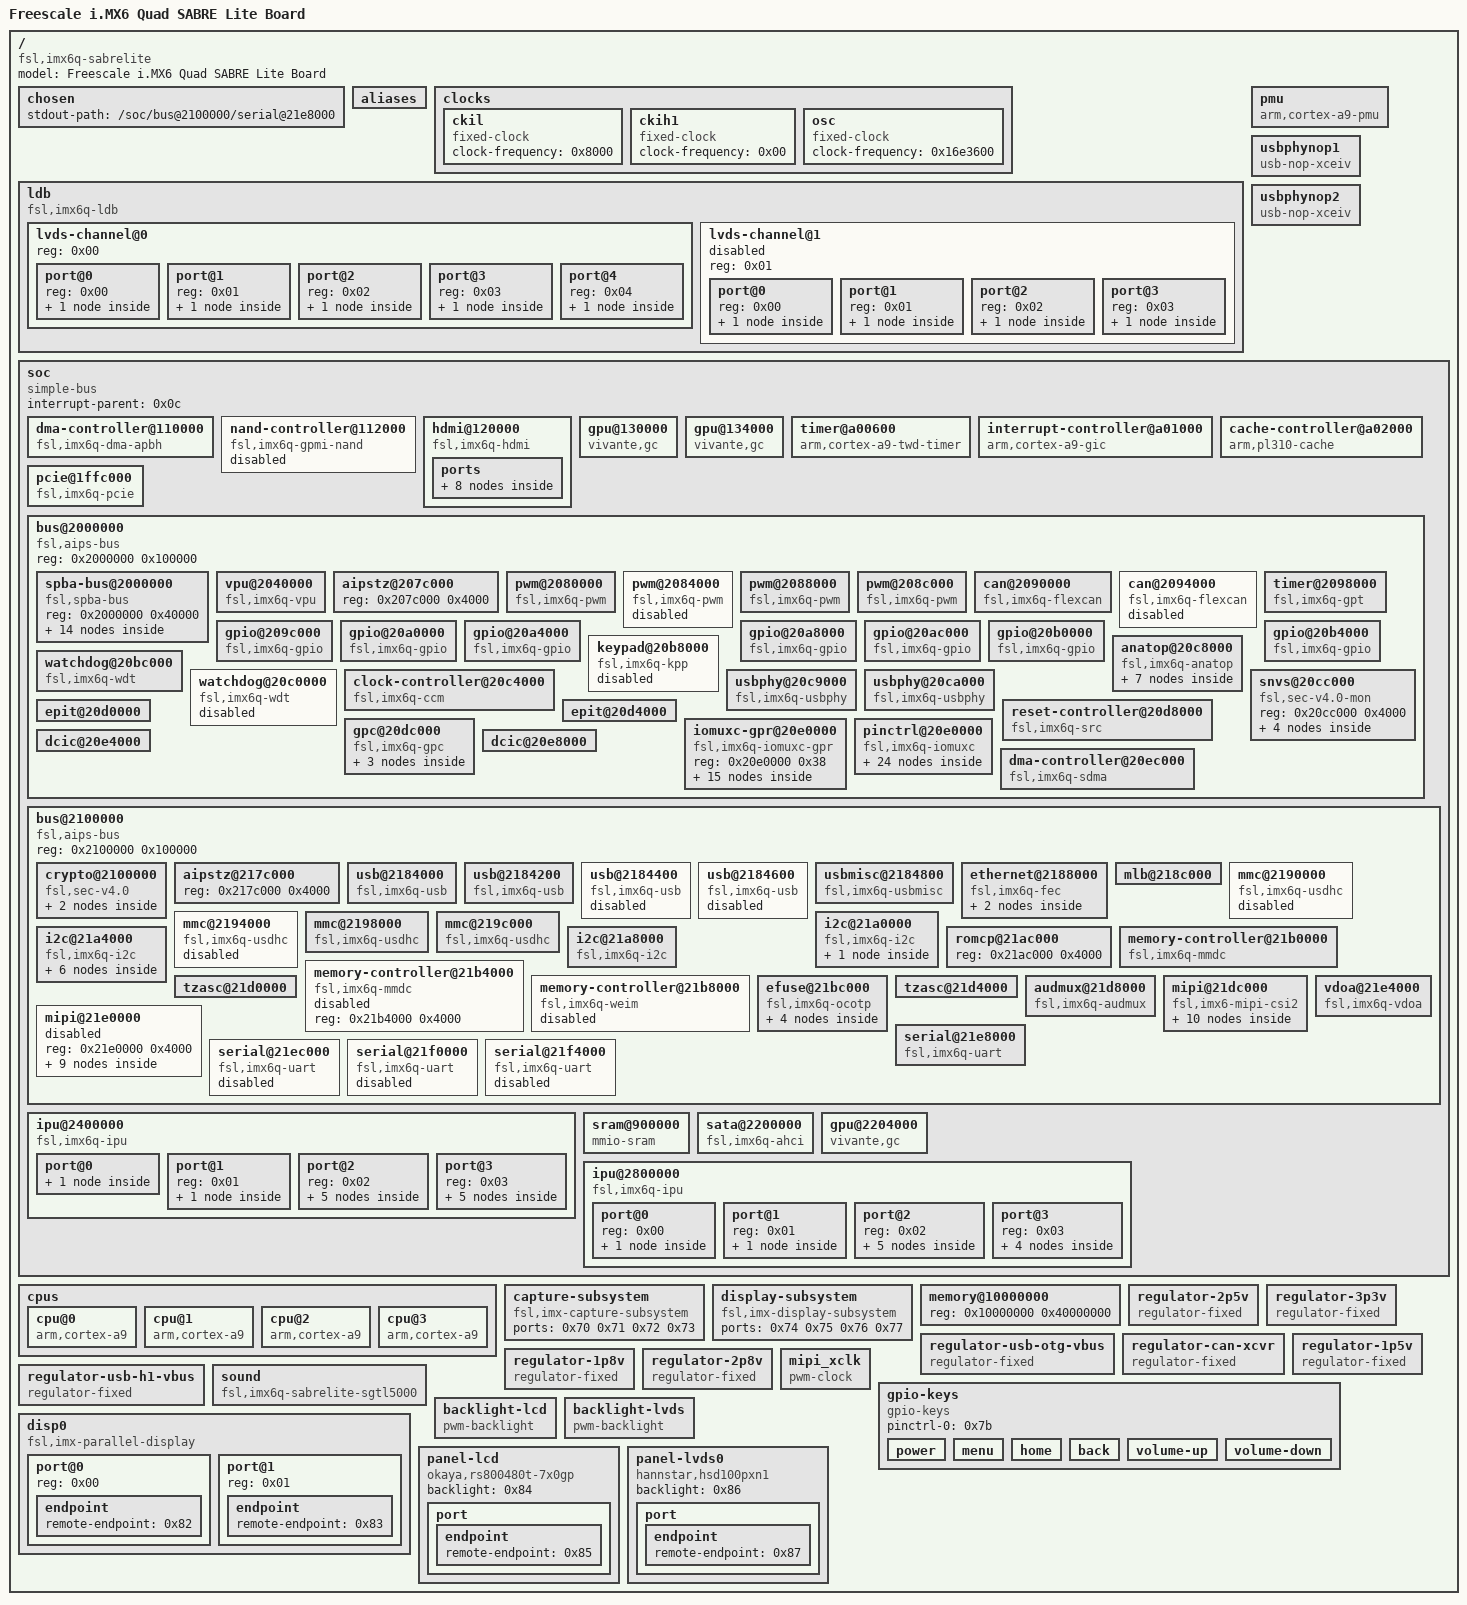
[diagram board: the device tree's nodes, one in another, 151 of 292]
/*
 * Copyright Linux Kernel Team
 *
 * SPDX-License-Identifier: GPL-2.0-only
 *
 * This file is derived from an intermediate build stage of the
 * Linux kernel. The licenses of all input files to this process
 * are compatible with GPL-2.0-only.
 */

/dts-v1/;

/ {
	#address-cells = <0x01>;
	#size-cells = <0x01>;
	model = "Freescale i.MX6 Quad SABRE Lite Board";
	compatible = "fsl,imx6q-sabrelite", "fsl,imx6q";

	chosen {
		stdout-path = "/soc/bus@2100000/serial@21e8000";
	};

	aliases {
		ethernet0 = "/soc/bus@2100000/ethernet@2188000";
		can0 = "/soc/bus@2000000/can@2090000";
		can1 = "/soc/bus@2000000/can@2094000";
		gpio0 = "/soc/bus@2000000/gpio@209c000";
		gpio1 = "/soc/bus@2000000/gpio@20a0000";
		gpio2 = "/soc/bus@2000000/gpio@20a4000";
		gpio3 = "/soc/bus@2000000/gpio@20a8000";
		gpio4 = "/soc/bus@2000000/gpio@20ac000";
		gpio5 = "/soc/bus@2000000/gpio@20b0000";
		gpio6 = "/soc/bus@2000000/gpio@20b4000";
		i2c0 = "/soc/bus@2100000/i2c@21a0000";
		i2c1 = "/soc/bus@2100000/i2c@21a4000";
		i2c2 = "/soc/bus@2100000/i2c@21a8000";
		ipu0 = "/soc/ipu@2400000";
		mmc0 = "/soc/bus@2100000/mmc@2198000";
		mmc1 = "/soc/bus@2100000/mmc@219c000";
		mmc2 = "/soc/bus@2100000/mmc@2198000";
		mmc3 = "/soc/bus@2100000/mmc@219c000";
		serial0 = "/soc/bus@2000000/spba-bus@2000000/serial@2020000";
		serial1 = "/soc/bus@2100000/serial@21e8000";
		serial2 = "/soc/bus@2100000/serial@21ec000";
		serial3 = "/soc/bus@2100000/serial@21f0000";
		serial4 = "/soc/bus@2100000/serial@21f4000";
		spi0 = "/soc/bus@2000000/spba-bus@2000000/spi@2008000";
		spi1 = "/soc/bus@2000000/spba-bus@2000000/spi@200c000";
		spi2 = "/soc/bus@2000000/spba-bus@2000000/spi@2010000";
		spi3 = "/soc/bus@2000000/spba-bus@2000000/spi@2014000";
		usb0 = "/soc/bus@2100000/usb@2184000";
		usb1 = "/soc/bus@2100000/usb@2184200";
		usb2 = "/soc/bus@2100000/usb@2184400";
		usb3 = "/soc/bus@2100000/usb@2184600";
		usbphy0 = "/soc/bus@2000000/usbphy@20c9000";
		usbphy1 = "/soc/bus@2000000/usbphy@20ca000";
		ipu1 = "/soc/ipu@2800000";
		spi4 = "/soc/bus@2000000/spba-bus@2000000/spi@2018000";
	};

	clocks {

		ckil {
			compatible = "fixed-clock";
			#clock-cells = <0x00>;
			clock-frequency = <0x8000>;
		};

		ckih1 {
			compatible = "fixed-clock";
			#clock-cells = <0x00>;
			clock-frequency = <0x00>;
		};

		osc {
			compatible = "fixed-clock";
			#clock-cells = <0x00>;
			clock-frequency = <0x16e3600>;
		};
	};

	ldb {
		#address-cells = <0x01>;
		#size-cells = <0x00>;
		compatible = "fsl,imx6q-ldb", "fsl,imx53-ldb";
		gpr = <0x01>;
		status = "okay";
		clocks = <0x02 0x21 0x02 0x22 0x02 0x27 0x02 0x28 0x02 0x29 0x02 0x2a 0x02 0x87 0x02 0x88>;
		clock-names = "di0_pll", "di1_pll", "di0_sel", "di1_sel", "di2_sel", "di3_sel", "di0", "di1";

		lvds-channel@0 {
			#address-cells = <0x01>;
			#size-cells = <0x00>;
			reg = <0x00>;
			status = "okay";

			port@0 {
				reg = <0x00>;

				endpoint {
					remote-endpoint = <0x03>;
					phandle = <0x5c>;
				};
			};

			port@1 {
				reg = <0x01>;

				endpoint {
					remote-endpoint = <0x04>;
					phandle = <0x60>;
				};
			};

			port@2 {
				reg = <0x02>;

				endpoint {
					remote-endpoint = <0x05>;
					phandle = <0x66>;
				};
			};

			port@3 {
				reg = <0x03>;

				endpoint {
					remote-endpoint = <0x06>;
					phandle = <0x6a>;
				};
			};

			port@4 {
				reg = <0x04>;

				endpoint {
					remote-endpoint = <0x07>;
					phandle = <0x87>;
				};
			};
		};

		lvds-channel@1 {
			#address-cells = <0x01>;
			#size-cells = <0x00>;
			reg = <0x01>;
			status = "disabled";

			port@0 {
				reg = <0x00>;

				endpoint {
					remote-endpoint = <0x08>;
					phandle = <0x5d>;
				};
			};

			port@1 {
				reg = <0x01>;

				endpoint {
					remote-endpoint = <0x09>;
					phandle = <0x61>;
				};
			};

			port@2 {
				reg = <0x02>;

				endpoint {
					remote-endpoint = <0x0a>;
					phandle = <0x67>;
				};
			};

			port@3 {
				reg = <0x03>;

				endpoint {
					remote-endpoint = <0x0b>;
					phandle = <0x6b>;
				};
			};
		};
	};

	pmu {
		compatible = "arm,cortex-a9-pmu";
		interrupt-parent = <0x0c>;
		interrupts = <0x00 0x5e 0x04>;
	};

	usbphynop1 {
		compatible = "usb-nop-xceiv";
		#phy-cells = <0x00>;
		phandle = <0x33>;
	};

	usbphynop2 {
		compatible = "usb-nop-xceiv";
		#phy-cells = <0x00>;
		phandle = <0x34>;
	};

	soc {
		#address-cells = <0x01>;
		#size-cells = <0x01>;
		compatible = "simple-bus";
		interrupt-parent = <0x0c>;
		ranges;

		dma-controller@110000 {
			compatible = "fsl,imx6q-dma-apbh", "fsl,imx28-dma-apbh";
			reg = <0x110000 0x2000>;
			interrupts = <0x00 0x0d 0x04 0x00 0x0d 0x04 0x00 0x0d 0x04 0x00 0x0d 0x04>;
			#dma-cells = <0x01>;
			dma-channels = <0x04>;
			clocks = <0x02 0x6a>;
			phandle = <0x0d>;
		};

		nand-controller@112000 {
			compatible = "fsl,imx6q-gpmi-nand";
			reg = <0x112000 0x2000 0x114000 0x2000>;
			reg-names = "gpmi-nand", "bch";
			interrupts = <0x00 0x0f 0x04>;
			interrupt-names = "bch";
			clocks = <0x02 0x98 0x02 0x99 0x02 0x97 0x02 0x96 0x02 0x95>;
			clock-names = "gpmi_io", "gpmi_apb", "gpmi_bch", "gpmi_bch_apb", "per1_bch";
			dmas = <0x0d 0x00>;
			dma-names = "rx-tx";
			status = "disabled";
		};

		hdmi@120000 {
			reg = <0x120000 0x9000>;
			interrupts = <0x00 0x73 0x04>;
			gpr = <0x01>;
			clocks = <0x02 0x7b 0x02 0x7c>;
			clock-names = "iahb", "isfr";
			status = "okay";
			compatible = "fsl,imx6q-hdmi";
			ddc-i2c-bus = <0x0e>;

			ports {
				#address-cells = <0x01>;
				#size-cells = <0x00>;

				port@0 {
					reg = <0x00>;

					endpoint {
						remote-endpoint = <0x0f>;
						phandle = <0x5a>;
					};
				};

				port@1 {
					reg = <0x01>;

					endpoint {
						remote-endpoint = <0x10>;
						phandle = <0x5e>;
					};
				};

				port@2 {
					reg = <0x02>;

					endpoint {
						remote-endpoint = <0x11>;
						phandle = <0x64>;
					};
				};

				port@3 {
					reg = <0x03>;

					endpoint {
						remote-endpoint = <0x12>;
						phandle = <0x68>;
					};
				};
			};
		};

		gpu@130000 {
			compatible = "vivante,gc";
			reg = <0x130000 0x4000>;
			interrupts = <0x00 0x09 0x04>;
			clocks = <0x02 0x1b 0x02 0x7a 0x02 0x4a>;
			clock-names = "bus", "core", "shader";
			power-domains = <0x13>;
			#cooling-cells = <0x02>;
		};

		gpu@134000 {
			compatible = "vivante,gc";
			reg = <0x134000 0x4000>;
			interrupts = <0x00 0x0a 0x04>;
			clocks = <0x02 0x1a 0x02 0x79>;
			clock-names = "bus", "core";
			power-domains = <0x13>;
			#cooling-cells = <0x02>;
		};

		timer@a00600 {
			compatible = "arm,cortex-a9-twd-timer";
			reg = <0xa00600 0x20>;
			interrupts = <0x01 0x0d 0xf01>;
			interrupt-parent = <0x14>;
			clocks = <0x02 0x0f>;
		};

		interrupt-controller@a01000 {
			compatible = "arm,cortex-a9-gic";
			#interrupt-cells = <0x03>;
			interrupt-controller;
			reg = <0xa01000 0x1000 0xa00100 0x100>;
			interrupt-parent = <0x14>;
			phandle = <0x14>;
		};

		cache-controller@a02000 {
			compatible = "arm,pl310-cache";
			reg = <0xa02000 0x1000>;
			interrupts = <0x00 0x5c 0x04>;
			cache-unified;
			cache-level = <0x02>;
			arm,tag-latency = <0x04 0x02 0x03>;
			arm,data-latency = <0x04 0x02 0x03>;
			arm,shared-override;
			phandle = <0x6c>;
		};

		pcie@1ffc000 {
			compatible = "fsl,imx6q-pcie";
			reg = <0x1ffc000 0x4000 0x1f00000 0x80000>;
			reg-names = "dbi", "config";
			#address-cells = <0x03>;
			#size-cells = <0x02>;
			device_type = "pci";
			bus-range = <0x00 0xff>;
			ranges = <0x81000000 0x00 0x00 0x1f80000 0x00 0x10000 0x82000000 0x00 0x1000000 0x1000000 0x00 0xf00000>;
			num-lanes = <0x01>;
			interrupts = <0x00 0x78 0x04>;
			interrupt-names = "msi";
			#interrupt-cells = <0x01>;
			interrupt-map-mask = <0x00 0x00 0x00 0x07>;
			interrupt-map = <0x00 0x00 0x00 0x01 0x0c 0x00 0x7b 0x04 0x00 0x00 0x00 0x02 0x0c 0x00 0x7a 0x04 0x00 0x00 0x00 0x03 0x0c 0x00 0x79 0x04 0x00 0x00 0x00 0x04 0x0c 0x00 0x78 0x04>;
			clocks = <0x02 0x90 0x02 0xce 0x02 0xbd>;
			clock-names = "pcie", "pcie_bus", "pcie_phy";
			status = "okay";
		};

		bus@2000000 {
			compatible = "fsl,aips-bus", "simple-bus";
			#address-cells = <0x01>;
			#size-cells = <0x01>;
			reg = <0x2000000 0x100000>;
			ranges;

			spba-bus@2000000 {
				compatible = "fsl,spba-bus", "simple-bus";
				#address-cells = <0x01>;
				#size-cells = <0x01>;
				reg = <0x2000000 0x40000>;
				ranges;

				spdif@2004000 {
					compatible = "fsl,imx35-spdif";
					reg = <0x2004000 0x4000>;
					interrupts = <0x00 0x34 0x04>;
					dmas = <0x15 0x0e 0x12 0x00 0x15 0x0f 0x12 0x00>;
					dma-names = "rx", "tx";
					clocks = <0x02 0xf4 0x02 0x03 0x02 0xc5 0x02 0x6b 0x02 0x00 0x02 0x76 0x02 0x3e 0x02 0x00 0x02 0x00 0x02 0x9c>;
					clock-names = "core", "rxtx0", "rxtx1", "rxtx2", "rxtx3", "rxtx4", "rxtx5", "rxtx6", "rxtx7", "spba";
					status = "disabled";
				};

				spi@2008000 {
					#address-cells = <0x01>;
					#size-cells = <0x00>;
					compatible = "fsl,imx6q-ecspi", "fsl,imx51-ecspi";
					reg = <0x2008000 0x4000>;
					interrupts = <0x00 0x1f 0x04>;
					clocks = <0x02 0x70 0x02 0x70>;
					clock-names = "ipg", "per";
					dmas = <0x15 0x03 0x07 0x01 0x15 0x04 0x07 0x02>;
					dma-names = "rx", "tx";
					status = "okay";
					cs-gpios = <0x16 0x13 0x01>;
					pinctrl-names = "default";
					pinctrl-0 = <0x17>;

					flash@0 {
						compatible = "sst,sst25vf016b", "jedec,spi-nor";
						spi-max-frequency = <0x1312d00>;
						reg = <0x00>;
					};
				};

				spi@200c000 {
					#address-cells = <0x01>;
					#size-cells = <0x00>;
					compatible = "fsl,imx6q-ecspi", "fsl,imx51-ecspi";
					reg = <0x200c000 0x4000>;
					interrupts = <0x00 0x20 0x04>;
					clocks = <0x02 0x71 0x02 0x71>;
					clock-names = "ipg", "per";
					dmas = <0x15 0x05 0x07 0x01 0x15 0x06 0x07 0x02>;
					dma-names = "rx", "tx";
					status = "disabled";
				};

				spi@2010000 {
					#address-cells = <0x01>;
					#size-cells = <0x00>;
					compatible = "fsl,imx6q-ecspi", "fsl,imx51-ecspi";
					reg = <0x2010000 0x4000>;
					interrupts = <0x00 0x21 0x04>;
					clocks = <0x02 0x72 0x02 0x72>;
					clock-names = "ipg", "per";
					dmas = <0x15 0x07 0x07 0x01 0x15 0x08 0x07 0x02>;
					dma-names = "rx", "tx";
					status = "disabled";
				};

				spi@2014000 {
					#address-cells = <0x01>;
					#size-cells = <0x00>;
					compatible = "fsl,imx6q-ecspi", "fsl,imx51-ecspi";
					reg = <0x2014000 0x4000>;
					interrupts = <0x00 0x22 0x04>;
					clocks = <0x02 0x73 0x02 0x73>;
					clock-names = "ipg", "per";
					dmas = <0x15 0x09 0x07 0x01 0x15 0x0a 0x07 0x02>;
					dma-names = "rx", "tx";
					status = "disabled";
				};

				serial@2020000 {
					compatible = "fsl,imx6q-uart", "fsl,imx21-uart";
					reg = <0x2020000 0x4000>;
					interrupts = <0x00 0x1a 0x04>;
					clocks = <0x02 0xa0 0x02 0xa1>;
					clock-names = "ipg", "per";
					dmas = <0x15 0x19 0x04 0x00 0x15 0x1a 0x04 0x00>;
					dma-names = "rx", "tx";
					status = "okay";
					pinctrl-names = "default";
					pinctrl-0 = <0x18>;
				};

				esai@2024000 {
					#sound-dai-cells = <0x00>;
					compatible = "fsl,imx35-esai";
					reg = <0x2024000 0x4000>;
					interrupts = <0x00 0x33 0x04>;
					clocks = <0x02 0xd0 0x02 0x76 0x02 0xd0 0x02 0x9c>;
					clock-names = "core", "extal", "fsys", "spba";
					dmas = <0x15 0x17 0x15 0x00 0x15 0x18 0x15 0x00>;
					dma-names = "rx", "tx";
					status = "disabled";
				};

				ssi@2028000 {
					#sound-dai-cells = <0x00>;
					compatible = "fsl,imx6q-ssi", "fsl,imx51-ssi";
					reg = <0x2028000 0x4000>;
					interrupts = <0x00 0x2e 0x04>;
					clocks = <0x02 0xb2 0x02 0x9d>;
					clock-names = "ipg", "baud";
					dmas = <0x15 0x25 0x01 0x00 0x15 0x26 0x01 0x00>;
					dma-names = "rx", "tx";
					fsl,fifo-depth = <0x0f>;
					status = "okay";
					phandle = <0x7d>;
				};

				ssi@202c000 {
					#sound-dai-cells = <0x00>;
					compatible = "fsl,imx6q-ssi", "fsl,imx51-ssi";
					reg = <0x202c000 0x4000>;
					interrupts = <0x00 0x2f 0x04>;
					clocks = <0x02 0xb3 0x02 0x9e>;
					clock-names = "ipg", "baud";
					dmas = <0x15 0x29 0x01 0x00 0x15 0x2a 0x01 0x00>;
					dma-names = "rx", "tx";
					fsl,fifo-depth = <0x0f>;
					status = "disabled";
				};

				ssi@2030000 {
					#sound-dai-cells = <0x00>;
					compatible = "fsl,imx6q-ssi", "fsl,imx51-ssi";
					reg = <0x2030000 0x4000>;
					interrupts = <0x00 0x30 0x04>;
					clocks = <0x02 0xb4 0x02 0x9f>;
					clock-names = "ipg", "baud";
					dmas = <0x15 0x2d 0x01 0x00 0x15 0x2e 0x01 0x00>;
					dma-names = "rx", "tx";
					fsl,fifo-depth = <0x0f>;
					status = "disabled";
				};

				asrc@2034000 {
					compatible = "fsl,imx53-asrc";
					reg = <0x2034000 0x4000>;
					interrupts = <0x00 0x32 0x04>;
					clocks = <0x02 0xd2 0x02 0xd3 0x02 0x00 0x02 0x00 0x02 0x00 0x02 0x00 0x02 0x00 0x02 0x00 0x02 0x00 0x02 0x00 0x02 0x00 0x02 0x00 0x02 0x00 0x02 0x00 0x02 0x00 0x02 0x6b 0x02 0x00 0x02 0x00 0x02 0x9c>;
					clock-names = "mem", "ipg", "asrck_0", "asrck_1", "asrck_2", "asrck_3", "asrck_4", "asrck_5", "asrck_6", "asrck_7", "asrck_8", "asrck_9", "asrck_a", "asrck_b", "asrck_c", "asrck_d", "asrck_e", "asrck_f", "spba";
					dmas = <0x15 0x11 0x17 0x01 0x15 0x12 0x17 0x01 0x15 0x13 0x17 0x01 0x15 0x14 0x17 0x01 0x15 0x15 0x17 0x01 0x15 0x16 0x17 0x01>;
					dma-names = "rxa", "rxb", "rxc", "txa", "txb", "txc";
					fsl,asrc-rate = <0xbb80>;
					fsl,asrc-width = <0x10>;
					status = "okay";
				};

				spba-bus@203c000 {
					reg = <0x203c000 0x4000>;
				};

				spi@2018000 {
					#address-cells = <0x01>;
					#size-cells = <0x00>;
					compatible = "fsl,imx6q-ecspi", "fsl,imx51-ecspi";
					reg = <0x2018000 0x4000>;
					interrupts = <0x00 0x23 0x04>;
					clocks = <0x02 0x74 0x02 0x74>;
					clock-names = "ipg", "per";
					dmas = <0x15 0x0b 0x07 0x01 0x15 0x0c 0x07 0x02>;
					dma-names = "rx", "tx";
					status = "disabled";
				};
			};

			vpu@2040000 {
				compatible = "fsl,imx6q-vpu", "cnm,coda960";
				reg = <0x2040000 0x3c000>;
				interrupts = <0x00 0x0c 0x04 0x00 0x03 0x04>;
				interrupt-names = "bit", "jpeg";
				clocks = <0x02 0xa8 0x02 0x8c>;
				clock-names = "per", "ahb";
				power-domains = <0x13>;
				resets = <0x19 0x01>;
				iram = <0x1a>;
			};

			aipstz@207c000 {
				reg = <0x207c000 0x4000>;
			};

			pwm@2080000 {
				#pwm-cells = <0x03>;
				compatible = "fsl,imx6q-pwm", "fsl,imx27-pwm";
				reg = <0x2080000 0x4000>;
				interrupts = <0x00 0x53 0x04>;
				clocks = <0x02 0x3e 0x02 0x91>;
				clock-names = "ipg", "per";
				status = "okay";
				pinctrl-names = "default";
				pinctrl-0 = <0x1b>;
				phandle = <0x7f>;
			};

			pwm@2084000 {
				#pwm-cells = <0x03>;
				compatible = "fsl,imx6q-pwm", "fsl,imx27-pwm";
				reg = <0x2084000 0x4000>;
				interrupts = <0x00 0x54 0x04>;
				clocks = <0x02 0x3e 0x02 0x92>;
				clock-names = "ipg", "per";
				status = "disabled";
			};

			pwm@2088000 {
				#pwm-cells = <0x03>;
				compatible = "fsl,imx6q-pwm", "fsl,imx27-pwm";
				reg = <0x2088000 0x4000>;
				interrupts = <0x00 0x55 0x04>;
				clocks = <0x02 0x3e 0x02 0x93>;
				clock-names = "ipg", "per";
				status = "okay";
				pinctrl-names = "default";
				pinctrl-0 = <0x1c>;
				phandle = <0x7a>;
			};

			pwm@208c000 {
				#pwm-cells = <0x03>;
				compatible = "fsl,imx6q-pwm", "fsl,imx27-pwm";
				reg = <0x208c000 0x4000>;
				interrupts = <0x00 0x56 0x04>;
				clocks = <0x02 0x3e 0x02 0x94>;
				clock-names = "ipg", "per";
				status = "okay";
				pinctrl-names = "default";
				pinctrl-0 = <0x1d>;
				phandle = <0x80>;
			};

			can@2090000 {
				compatible = "fsl,imx6q-flexcan";
				reg = <0x2090000 0x4000>;
				interrupts = <0x00 0x6e 0x04>;
				clocks = <0x02 0x6c 0x02 0x6d>;
				clock-names = "ipg", "per";
				fsl,stop-mode = <0x01 0x34 0x1c>;
				status = "okay";
				pinctrl-names = "default";
				pinctrl-0 = <0x1e>;
				xceiver-supply = <0x1f>;
			};

			can@2094000 {
				compatible = "fsl,imx6q-flexcan";
				reg = <0x2094000 0x4000>;
				interrupts = <0x00 0x6f 0x04>;
				clocks = <0x02 0x6e 0x02 0x6f>;
				clock-names = "ipg", "per";
				fsl,stop-mode = <0x01 0x34 0x1d>;
				status = "disabled";
			};

			timer@2098000 {
				compatible = "fsl,imx6q-gpt", "fsl,imx31-gpt";
				reg = <0x2098000 0x4000>;
				interrupts = <0x00 0x37 0x04>;
				clocks = <0x02 0x77 0x02 0x78 0x02 0xed>;
				clock-names = "ipg", "per", "osc_per";
			};

			gpio@209c000 {
				compatible = "fsl,imx6q-gpio", "fsl,imx35-gpio";
				reg = <0x209c000 0x4000>;
				interrupts = <0x00 0x42 0x04 0x00 0x43 0x04>;
				gpio-controller;
				#gpio-cells = <0x02>;
				interrupt-controller;
				#interrupt-cells = <0x02>;
				gpio-ranges = <0x20 0x00 0x88 0x02 0x20 0x02 0x8d 0x01 0x20 0x03 0x8b 0x01 0x20 0x04 0x8e 0x02 0x20 0x06 0x8c 0x01 0x20 0x07 0x90 0x02 0x20 0x09 0x8a 0x01 0x20 0x0a 0xd5 0x03 0x20 0x0d 0x14 0x01 0x20 0x0e 0x13 0x01 0x20 0x0f 0x15 0x01 0x20 0x10 0xd0 0x01 0x20 0x11 0xcf 0x01 0x20 0x12 0xd2 0x03 0x20 0x15 0xd1 0x01 0x20 0x16 0x74 0x0a>;
				phandle = <0x48>;
			};

			gpio@20a0000 {
				compatible = "fsl,imx6q-gpio", "fsl,imx35-gpio";
				reg = <0x20a0000 0x4000>;
				interrupts = <0x00 0x44 0x04 0x00 0x45 0x04>;
				gpio-controller;
				#gpio-cells = <0x02>;
				interrupt-controller;
				#interrupt-cells = <0x02>;
				gpio-ranges = <0x20 0x00 0xbf 0x10 0x20 0x10 0x37 0x0e 0x20 0x1e 0x23 0x01 0x20 0x1f 0x2c 0x01>;
				phandle = <0x3c>;
			};

			gpio@20a4000 {
				compatible = "fsl,imx6q-gpio", "fsl,imx35-gpio";
				reg = <0x20a4000 0x4000>;
				interrupts = <0x00 0x46 0x04 0x00 0x47 0x04>;
				gpio-controller;
				#gpio-cells = <0x02>;
				interrupt-controller;
				#interrupt-cells = <0x02>;
				gpio-ranges = <0x20 0x00 0x45 0x10 0x20 0x10 0x24 0x08 0x20 0x18 0x2d 0x08>;
				phandle = <0x16>;
			};

			gpio@20a8000 {
				compatible = "fsl,imx6q-gpio", "fsl,imx35-gpio";
				reg = <0x20a8000 0x4000>;
				interrupts = <0x00 0x48 0x04 0x00 0x49 0x04>;
				gpio-controller;
				#gpio-cells = <0x02>;
				interrupt-controller;
				#interrupt-cells = <0x02>;
				gpio-ranges = <0x20 0x05 0x95 0x01 0x20 0x06 0x7e 0x0a 0x20 0x10 0x57 0x10>;
				phandle = <0x7c>;
			};

			gpio@20ac000 {
				compatible = "fsl,imx6q-gpio", "fsl,imx35-gpio";
				reg = <0x20ac000 0x4000>;
				interrupts = <0x00 0x4a 0x04 0x00 0x4b 0x04>;
				gpio-controller;
				#gpio-cells = <0x02>;
				interrupt-controller;
				#interrupt-cells = <0x02>;
				gpio-ranges = <0x20 0x00 0x55 0x01 0x20 0x02 0x22 0x01 0x20 0x04 0x35 0x01 0x20 0x05 0x67 0x0d 0x20 0x12 0x96 0x0e>;
			};

			gpio@20b0000 {
				compatible = "fsl,imx6q-gpio", "fsl,imx35-gpio";
				reg = <0x20b0000 0x4000>;
				interrupts = <0x00 0x4c 0x04 0x00 0x4d 0x04>;
				gpio-controller;
				#gpio-cells = <0x02>;
				interrupt-controller;
				#interrupt-cells = <0x02>;
				gpio-ranges = <0x20 0x00 0xa4 0x06 0x20 0x06 0x36 0x01 0x20 0x07 0xb5 0x05 0x20 0x0e 0xba 0x03 0x20 0x11 0xaa 0x02 0x20 0x13 0x16 0x0c 0x20 0x1f 0x56 0x01>;
				phandle = <0x45>;
			};

			gpio@20b4000 {
				compatible = "fsl,imx6q-gpio", "fsl,imx35-gpio";
				reg = <0x20b4000 0x4000>;
				interrupts = <0x00 0x4e 0x04 0x00 0x4f 0x04>;
				gpio-controller;
				#gpio-cells = <0x02>;
				interrupt-controller;
				#interrupt-cells = <0x02>;
				gpio-ranges = <0x20 0x00 0xac 0x09 0x20 0x09 0xbd 0x02 0x20 0x0b 0x92 0x03>;
				phandle = <0x39>;
			};

			keypad@20b8000 {
				compatible = "fsl,imx6q-kpp", "fsl,imx21-kpp";
				reg = <0x20b8000 0x4000>;
				interrupts = <0x00 0x52 0x04>;
				clocks = <0x02 0x3e>;
				status = "disabled";
			};

			watchdog@20bc000 {
				compatible = "fsl,imx6q-wdt", "fsl,imx21-wdt";
				reg = <0x20bc000 0x4000>;
				interrupts = <0x00 0x50 0x04>;
				clocks = <0x02 0x3e>;
			};

			watchdog@20c0000 {
				compatible = "fsl,imx6q-wdt", "fsl,imx21-wdt";
				reg = <0x20c0000 0x4000>;
				interrupts = <0x00 0x51 0x04>;
				clocks = <0x02 0x3e>;
				status = "disabled";
			};

			clock-controller@20c4000 {
				compatible = "fsl,imx6q-ccm";
				reg = <0x20c4000 0x4000>;
				interrupts = <0x00 0x57 0x04 0x00 0x58 0x04>;
				#clock-cells = <0x01>;
				assigned-clocks = <0x02 0x21 0x02 0x22>;
				assigned-clock-parents = <0x02 0xac 0x02 0xac>;
				phandle = <0x02>;
			};

			anatop@20c8000 {
				compatible = "fsl,imx6q-anatop", "syscon", "simple-mfd";
				reg = <0x20c8000 0x1000>;
				interrupts = <0x00 0x31 0x04 0x00 0x36 0x04 0x00 0x7f 0x04>;
				phandle = <0x21>;

				regulator-1p1 {
					compatible = "fsl,anatop-regulator";
					regulator-name = "vdd1p1";
					regulator-min-microvolt = <0xf4240>;
					regulator-max-microvolt = <0x124f80>;
					regulator-always-on;
					anatop-reg-offset = <0x110>;
					anatop-vol-bit-shift = <0x08>;
					anatop-vol-bit-width = <0x05>;
					anatop-min-bit-val = <0x04>;
					anatop-min-voltage = "", "\f5";
					anatop-max-voltage = <0x14fb18>;
					anatop-enable-bit = <0x00>;
				};

				regulator-3p0 {
					compatible = "fsl,anatop-regulator";
					regulator-name = "vdd3p0";
					regulator-min-microvolt = <0x2ab980>;
					regulator-max-microvolt = <0x3010b0>;
					regulator-always-on;
					anatop-reg-offset = <0x120>;
					anatop-vol-bit-shift = <0x08>;
					anatop-vol-bit-width = <0x05>;
					anatop-min-bit-val = <0x00>;
					anatop-min-voltage = <0x280de8>;
					anatop-max-voltage = <0x33e140>;
					anatop-enable-bit = <0x00>;
				};

				regulator-2p5 {
					compatible = "fsl,anatop-regulator";
					regulator-name = "vdd2p5";
					regulator-min-microvolt = <0x225510>;
					regulator-max-microvolt = <0x29f630>;
					regulator-always-on;
					anatop-reg-offset = <0x130>;
					anatop-vol-bit-shift = <0x08>;
					anatop-vol-bit-width = <0x05>;
					anatop-min-bit-val = <0x00>;
					anatop-min-voltage = <0x200b20>;
					anatop-max-voltage = <0x2bde78>;
					anatop-enable-bit = <0x00>;
				};

				regulator-vddcore {
					compatible = "fsl,anatop-regulator";
					regulator-name = "vddarm";
					regulator-min-microvolt = <0xb1008>;
					regulator-max-microvolt = <0x162010>;
					regulator-always-on;
					anatop-reg-offset = <0x140>;
					anatop-vol-bit-shift = <0x00>;
					anatop-vol-bit-width = <0x05>;
					anatop-delay-reg-offset = <0x170>;
					anatop-delay-bit-shift = <0x18>;
					anatop-delay-bit-width = <0x02>;
					anatop-min-bit-val = <0x01>;
					anatop-min-voltage = <0xb1008>;
					anatop-max-voltage = <0x162010>;
					phandle = <0x6d>;
				};

				regulator-vddpu {
					compatible = "fsl,anatop-regulator";
					regulator-name = "vddpu";
					regulator-min-microvolt = <0xb1008>;
					regulator-max-microvolt = <0x162010>;
					regulator-enable-ramp-delay = <0x17c>;
					anatop-reg-offset = <0x140>;
					anatop-vol-bit-shift = <0x09>;
					anatop-vol-bit-width = <0x05>;
					anatop-delay-reg-offset = <0x170>;
					anatop-delay-bit-shift = <0x1a>;
					anatop-delay-bit-width = <0x02>;
					anatop-min-bit-val = <0x01>;
					anatop-min-voltage = <0xb1008>;
					anatop-max-voltage = <0x162010>;
					phandle = <0x25>;
				};

				regulator-vddsoc {
					compatible = "fsl,anatop-regulator";
					regulator-name = "vddsoc";
					regulator-min-microvolt = <0xb1008>;
					regulator-max-microvolt = <0x162010>;
					regulator-always-on;
					anatop-reg-offset = <0x140>;
					anatop-vol-bit-shift = <0x12>;
					anatop-vol-bit-width = <0x05>;
					anatop-delay-reg-offset = <0x170>;
					anatop-delay-bit-shift = <0x1c>;
					anatop-delay-bit-width = <0x02>;
					anatop-min-bit-val = <0x01>;
					anatop-min-voltage = <0xb1008>;
					anatop-max-voltage = <0x162010>;
					phandle = <0x6e>;
				};

				tempmon {
					compatible = "fsl,imx6q-tempmon";
					interrupt-parent = <0x0c>;
					interrupts = <0x00 0x31 0x04>;
					fsl,tempmon = <0x21>;
					nvmem-cells = <0x22 0x23>;
					nvmem-cell-names = "calib", "temp_grade";
					clocks = <0x02 0xac>;
					#thermal-sensor-cells = <0x00>;
				};
			};

			usbphy@20c9000 {
				compatible = "fsl,imx6q-usbphy", "fsl,imx23-usbphy";
				reg = <0x20c9000 0x1000>;
				interrupts = <0x00 0x2c 0x04>;
				clocks = <0x02 0xb6>;
				fsl,anatop = <0x21>;
				phandle = <0x2d>;
			};

			usbphy@20ca000 {
				compatible = "fsl,imx6q-usbphy", "fsl,imx23-usbphy";
				reg = <0x20ca000 0x1000>;
				interrupts = <0x00 0x2d 0x04>;
				clocks = <0x02 0xb7>;
				fsl,anatop = <0x21>;
				phandle = <0x31>;
			};

			snvs@20cc000 {
				compatible = "fsl,sec-v4.0-mon", "syscon", "simple-mfd";
				reg = <0x20cc000 0x4000>;
				phandle = <0x24>;

				snvs-rtc-lp {
					compatible = "fsl,sec-v4.0-mon-rtc-lp";
					regmap = <0x24>;
					offset = <0x34>;
					interrupts = <0x00 0x13 0x04 0x00 0x14 0x04>;
				};

				snvs-poweroff {
					compatible = "syscon-poweroff";
					regmap = <0x24>;
					offset = <0x38>;
					value = <0x60>;
					mask = <0x60>;
					status = "disabled";
				};

				snvs-powerkey {
					compatible = "fsl,sec-v4.0-pwrkey";
					regmap = <0x24>;
					interrupts = <0x00 0x04 0x04>;
					linux,keycode = <0x74>;
					wakeup-source;
					status = "disabled";
				};

				snvs-lpgpr {
					compatible = "fsl,imx6q-snvs-lpgpr";
				};
			};

			epit@20d0000 {
				reg = <0x20d0000 0x4000>;
				interrupts = <0x00 0x38 0x04>;
			};

			epit@20d4000 {
				reg = <0x20d4000 0x4000>;
				interrupts = <0x00 0x39 0x04>;
			};

			reset-controller@20d8000 {
				compatible = "fsl,imx6q-src", "fsl,imx51-src";
				reg = <0x20d8000 0x4000>;
				interrupts = <0x00 0x5b 0x04 0x00 0x60 0x04>;
				#reset-cells = <0x01>;
				phandle = <0x19>;
			};

			gpc@20dc000 {
				compatible = "fsl,imx6q-gpc";
				reg = <0x20dc000 0x4000>;
				interrupt-controller;
				#interrupt-cells = <0x03>;
				interrupts = <0x00 0x59 0x04>;
				interrupt-parent = <0x14>;
				clocks = <0x02 0x3e>;
				clock-names = "ipg";
				phandle = <0x0c>;

				pgc {
					#address-cells = <0x01>;
					#size-cells = <0x00>;

					power-domain@0 {
						reg = <0x00>;
						#power-domain-cells = <0x00>;
					};

					power-domain@1 {
						reg = <0x01>;
						#power-domain-cells = <0x00>;
						power-supply = <0x25>;
						clocks = <0x02 0x7a 0x02 0x4a 0x02 0x79 0x02 0x1a 0x02 0x8f 0x02 0xa8>;
						phandle = <0x13>;
					};
				};
			};

			iomuxc-gpr@20e0000 {
				compatible = "fsl,imx6q-iomuxc-gpr", "syscon", "simple-mfd";
				reg = <0x20e0000 0x38>;
				phandle = <0x01>;

				mux-controller {
					compatible = "mmio-mux";
					#mux-control-cells = <0x01>;
					mux-reg-masks = <0x04 0x80000 0x04 0x100000 0x0c 0x0c 0x0c 0xc0 0x0c 0x300 0x28 0x03 0x28 0x0c>;
					phandle = <0x26>;
				};

				ipu1_csi0_mux {
					compatible = "video-mux";
					mux-controls = <0x26 0x00>;
					#address-cells = <0x01>;
					#size-cells = <0x00>;

					port@0 {
						reg = <0x00>;

						endpoint {
							remote-endpoint = <0x27>;
							phandle = <0x4c>;
						};
					};

					port@1 {
						reg = <0x01>;

						endpoint {
							remote-endpoint = <0x28>;
							phandle = <0x49>;
						};
					};

					port@2 {
						reg = <0x02>;

						endpoint {
							remote-endpoint = <0x29>;
							phandle = <0x57>;
						};
					};
				};

				ipu2_csi1_mux {
					compatible = "video-mux";
					mux-controls = <0x26 0x01>;
					#address-cells = <0x01>;
					#size-cells = <0x00>;

					port@0 {
						reg = <0x00>;

						endpoint {
							remote-endpoint = <0x2a>;
							phandle = <0x4f>;
						};
					};

					port@1 {
						reg = <0x01>;

						endpoint {
						};
					};

					port@2 {
						reg = <0x02>;

						endpoint {
							remote-endpoint = <0x2b>;
							phandle = <0x63>;
						};
					};
				};
			};

			pinctrl@20e0000 {
				compatible = "fsl,imx6q-iomuxc";
				reg = <0x20e0000 0x4000>;
				pinctrl-names = "default";
				pinctrl-0 = <0x2c>;
				phandle = <0x20>;

				imx6q-sabrelite {

					hoggrp {
						fsl,pins = <0x220 0x5f0 0x00 0x00 0x00 0x30b0>;
						phandle = <0x2c>;
					};

					audmuxgrp {
						fsl,pins = <0x54 0x368 0x7b4 0x03 0x00 0x130b0 0x35c 0x744 0x7c4 0x03 0x01 0x130b0 0x50 0x364 0x7b8 0x03 0x00 0x110b0 0x4c 0x360 0x7c8 0x03 0x00 0x130b0>;
						phandle = <0x4b>;
					};

					can1grp {
						fsl,pins = <0x208 0x5d8 0x00 0x02 0x00 0x1b0b0 0x20c 0x5dc 0x7e4 0x02 0x00 0x1b0b0>;
						phandle = <0x1e>;
					};

					can-xcvrgrp {
						fsl,pins = <0x234 0x604 0x00 0x05 0x00 0x1b0b0>;
						phandle = <0x78>;
					};

					ecspi1grp {
						fsl,pins = <0x94 0x3a8 0x7f8 0x01 0x00 0x100b1 0x98 0x3ac 0x7fc 0x01 0x00 0x100b1 0x90 0x3a4 0x7f4 0x01 0x00 0x100b1 0x9c 0x3b0 0x00 0x05 0x00 0xb1>;
						phandle = <0x17>;
					};

					enetgrp {
						fsl,pins = <0x1d0 0x4e4 0x840 0x01 0x00 0x100b0 0x1f4 0x508 0x00 0x01 0x00 0x100b0 0x58 0x36c 0x00 0x01 0x00 0x10030 0x5c 0x370 0x00 0x01 0x00 0x10030 0x60 0x374 0x00 0x01 0x00 0x10030 0x64 0x378 0x00 0x01 0x00 0x10030 0x68 0x37c 0x00 0x01 0x00 0x10030 0x74 0x388 0x00 0x01 0x00 0x10030 0x1d4 0x4e8 0x00 0x01 0x00 0x100b0 0x84 0x398 0x844 0x01 0x00 0x1b030 0x70 0x384 0x848 0x01 0x00 0x1b030 0x78 0x38c 0x84c 0x01 0x00 0x1b030 0x7c 0x390 0x850 0x01 0x00 0x1b030 0x80 0x394 0x854 0x01 0x00 0x1b030 0x6c 0x380 0x858 0x01 0x00 0x1b030 0xac 0x3c0 0x00 0x05 0x00 0xb0>;
						phandle = <0x36>;
					};

					gpio-keysgrp {
						fsl,pins = <0x308 0x6f0 0x00 0x05 0x00 0x1b0b0 0x300 0x6e8 0x00 0x05 0x00 0x1b0b0 0x30c 0x6f4 0x00 0x05 0x00 0x1b0b0 0x304 0x6ec 0x00 0x05 0x00 0x1b0b0 0x250 0x620 0x00 0x05 0x00 0x1b0b0 0x254 0x624 0x00 0x05 0x00 0x1b0b0>;
						phandle = <0x7b>;
					};

					i2c1grp {
						fsl,pins = <0xa4 0x3b8 0x898 0x06 0x00 0x4001b8b1 0xc4 0x3d8 0x89c 0x01 0x00 0x4001b8b1>;
						phandle = <0x3d>;
					};

					i2c2grp {
						fsl,pins = <0x210 0x5e0 0x8a0 0x04 0x01 0x4001b8b1 0x214 0x5e4 0x8a4 0x04 0x01 0x4001b8b1>;
						phandle = <0x3f>;
					};

					i2c3grp {
						fsl,pins = <0x23c 0x60c 0x8a8 0x06 0x02 0x4001b8b1 0x248 0x618 0x8ac 0x06 0x02 0x4001b8b1>;
						phandle = <0x4a>;
					};

					ipu1csi0grp {
						fsl,pins = <0x288 0x658 0x00 0x00 0x00 0x1b0b0 0x28c 0x65c 0x00 0x00 0x00 0x1b0b0 0x290 0x660 0x00 0x00 0x00 0x1b0b0 0x294 0x664 0x00 0x00 0x00 0x1b0b0 0x298 0x668 0x00 0x00 0x00 0x1b0b0 0x29c 0x66c 0x00 0x00 0x00 0x1b0b0 0x2a0 0x670 0x00 0x00 0x00 0x1b0b0 0x2a4 0x674 0x00 0x00 0x00 0x1b0b0 0x258 0x628 0x00 0x00 0x00 0x1b0b0 0x25c 0x62c 0x00 0x00 0x00 0x1b0b0 0x264 0x634 0x00 0x00 0x00 0x1b0b0 0x260 0x630 0x00 0x00 0x00 0x1b0b0>;
						phandle = <0x56>;
					};

					j15grp {
						fsl,pins = <0x15c 0x470 0x00 0x00 0x00 0x10 0x160 0x474 0x00 0x00 0x00 0x10 0x164 0x478 0x00 0x00 0x00 0x10 0x168 0x47c 0x00 0x00 0x00 0x10 0x170 0x484 0x00 0x00 0x00 0x10 0x174 0x488 0x00 0x00 0x00 0x10 0x178 0x48c 0x00 0x00 0x00 0x10 0x17c 0x490 0x00 0x00 0x00 0x10 0x180 0x494 0x00 0x00 0x00 0x10 0x184 0x498 0x00 0x00 0x00 0x10 0x188 0x49c 0x00 0x00 0x00 0x10 0x18c 0x4a0 0x00 0x00 0x00 0x10 0x190 0x4a4 0x00 0x00 0x00 0x10 0x194 0x4a8 0x00 0x00 0x00 0x10 0x198 0x4ac 0x00 0x00 0x00 0x10 0x19c 0x4b0 0x00 0x00 0x00 0x10 0x1a0 0x4b4 0x00 0x00 0x00 0x10 0x1a4 0x4b8 0x00 0x00 0x00 0x10 0x1a8 0x4bc 0x00 0x00 0x00 0x10 0x1ac 0x4c0 0x00 0x00 0x00 0x10 0x1b0 0x4c4 0x00 0x00 0x00 0x10 0x1b4 0x4c8 0x00 0x00 0x00 0x10 0x1b8 0x4cc 0x00 0x00 0x00 0x10 0x1bc 0x4d0 0x00 0x00 0x00 0x10 0x1c0 0x4d4 0x00 0x00 0x00 0x10 0x1c4 0x4d8 0x00 0x00 0x00 0x10 0x1c8 0x4dc 0x00 0x00 0x00 0x10 0x1cc 0x4e0 0x00 0x00 0x00 0x10>;
						phandle = <0x81>;
					};

					ov5640grp {
						fsl,pins = <0x310 0x6f8 0x00 0x05 0x00 0xb0 0x2dc 0x6c4 0x00 0x05 0x00 0xb0b0>;
						phandle = <0x40>;
					};

					ov5642grp {
						fsl,pins = <0x340 0x728 0x00 0x05 0x00 0x1b0b0 0x230 0x600 0x00 0x05 0x00 0x1b0b0 0x244 0x614 0x00 0x05 0x00 0x130b0 0x22c 0x5fc 0x00 0x04 0x00 0xb0>;
						phandle = <0x47>;
					};

					pwm1grp {
						fsl,pins = <0x344 0x72c 0x00 0x03 0x00 0x1b0b1>;
						phandle = <0x1b>;
					};

					pwm3grp {
						fsl,pins = <0x33c 0x724 0x00 0x02 0x00 0x1b0b1>;
						phandle = <0x1c>;
					};

					pwm4grp {
						fsl,pins = <0x348 0x730 0x00 0x02 0x00 0x1b0b1>;
						phandle = <0x1d>;
					};

					uart1grp {
						fsl,pins = <0x2a8 0x690 0x00 0x01 0x00 0x1b0b1 0x2ac 0x694 0x920 0x01 0x03 0x1b0b1>;
						phandle = <0x18>;
					};

					uart2grp {
						fsl,pins = <0xbc 0x3d0 0x00 0x04 0x00 0x1b0b1 0xc0 0x3d4 0x928 0x04 0x01 0x1b0b1>;
						phandle = <0x55>;
					};

					usbh1grp {
						fsl,pins = <0x24c 0x61c 0x00 0x05 0x00 0x30b0>;
						phandle = <0x79>;
					};

					usbotggrp {
						fsl,pins = <0x224 0x5f4 0x04 0x03 0xff0d0101 0x17059 0x218 0x5e8 0x944 0x02 0x01 0x1b0b0 0xa8 0x3bc 0x00 0x05 0x00 0xb0>;
						phandle = <0x30>;
					};

					usdhc3grp {
						fsl,pins = <0x2b8 0x6a0 0x00 0x00 0x00 0x17059 0x2bc 0x6a4 0x00 0x00 0x00 0x10059 0x2c0 0x6a8 0x00 0x00 0x00 0x17059 0x2c4 0x6ac 0x00 0x00 0x00 0x17059 0x2c8 0x6b0 0x00 0x00 0x00 0x17059 0x2cc 0x6b4 0x00 0x00 0x00 0x17059 0x2b0 0x698 0x00 0x05 0x00 0x1b0b0 0x2b4 0x69c 0x00 0x05 0x00 0x1f0b0>;
						phandle = <0x38>;
					};

					usdhc4grp {
						fsl,pins = <0x2f4 0x6dc 0x00 0x00 0x00 0x17059 0x2f8 0x6e0 0x00 0x00 0x00 0x10059 0x31c 0x704 0x00 0x01 0x00 0x17059 0x320 0x708 0x00 0x01 0x00 0x17059 0x324 0x70c 0x00 0x01 0x00 0x17059 0x328 0x710 0x00 0x01 0x00 0x17059 0x314 0x6fc 0x00 0x05 0x00 0x1b0b0>;
						phandle = <0x3b>;
					};
				};
			};

			dcic@20e4000 {
				reg = <0x20e4000 0x4000>;
				interrupts = <0x00 0x7c 0x04>;
			};

			dcic@20e8000 {
				reg = <0x20e8000 0x4000>;
				interrupts = <0x00 0x7d 0x04>;
			};

			dma-controller@20ec000 {
				compatible = "fsl,imx6q-sdma", "fsl,imx35-sdma";
				reg = <0x20ec000 0x4000>;
				interrupts = <0x00 0x02 0x04>;
				clocks = <0x02 0x3e 0x02 0x9b>;
				clock-names = "ipg", "ahb";
				#dma-cells = <0x03>;
				fsl,sdma-ram-script-name = "imx/sdma/sdma-imx6q.bin";
				phandle = <0x15>;
			};
		};

		bus@2100000 {
			compatible = "fsl,aips-bus", "simple-bus";
			#address-cells = <0x01>;
			#size-cells = <0x01>;
			reg = <0x2100000 0x100000>;
			ranges;

			crypto@2100000 {
				compatible = "fsl,sec-v4.0";
				#address-cells = <0x01>;
				#size-cells = <0x01>;
				reg = <0x2100000 0x10000>;
				ranges = <0x00 0x2100000 0x10000>;
				clocks = <0x02 0xf1 0x02 0xf2 0x02 0xf3 0x02 0xc4>;
				clock-names = "mem", "aclk", "ipg", "emi_slow";

				jr@1000 {
					compatible = "fsl,sec-v4.0-job-ring";
					reg = <0x1000 0x1000>;
					interrupts = <0x00 0x69 0x04>;
				};

				jr@2000 {
					compatible = "fsl,sec-v4.0-job-ring";
					reg = <0x2000 0x1000>;
					interrupts = <0x00 0x6a 0x04>;
				};
			};

			aipstz@217c000 {
				reg = <0x217c000 0x4000>;
			};

			usb@2184000 {
				compatible = "fsl,imx6q-usb", "fsl,imx27-usb";
				reg = <0x2184000 0x200>;
				interrupts = <0x00 0x2b 0x04>;
				clocks = <0x02 0xa2>;
				fsl,usbphy = <0x2d>;
				fsl,usbmisc = <0x2e 0x00>;
				ahb-burst-config = <0x00>;
				tx-burst-size-dword = <0x10>;
				rx-burst-size-dword = <0x10>;
				status = "okay";
				vbus-supply = <0x2f>;
				pinctrl-names = "default";
				pinctrl-0 = <0x30>;
				disable-over-current;
			};

			usb@2184200 {
				compatible = "fsl,imx6q-usb", "fsl,imx27-usb";
				reg = <0x2184200 0x200>;
				interrupts = <0x00 0x28 0x04>;
				clocks = <0x02 0xa2>;
				fsl,usbphy = <0x31>;
				fsl,usbmisc = <0x2e 0x01>;
				dr_mode = "host";
				ahb-burst-config = <0x00>;
				tx-burst-size-dword = <0x10>;
				rx-burst-size-dword = <0x10>;
				status = "okay";
				vbus-supply = <0x32>;
			};

			usb@2184400 {
				compatible = "fsl,imx6q-usb", "fsl,imx27-usb";
				reg = <0x2184400 0x200>;
				interrupts = <0x00 0x29 0x04>;
				clocks = <0x02 0xa2>;
				fsl,usbphy = <0x33>;
				phy_type = "hsic";
				fsl,usbmisc = <0x2e 0x02>;
				dr_mode = "host";
				ahb-burst-config = <0x00>;
				tx-burst-size-dword = <0x10>;
				rx-burst-size-dword = <0x10>;
				status = "disabled";
			};

			usb@2184600 {
				compatible = "fsl,imx6q-usb", "fsl,imx27-usb";
				reg = <0x2184600 0x200>;
				interrupts = <0x00 0x2a 0x04>;
				clocks = <0x02 0xa2>;
				fsl,usbphy = <0x34>;
				phy_type = "hsic";
				fsl,usbmisc = <0x2e 0x03>;
				dr_mode = "host";
				ahb-burst-config = <0x00>;
				tx-burst-size-dword = <0x10>;
				rx-burst-size-dword = <0x10>;
				status = "disabled";
			};

			usbmisc@2184800 {
				#index-cells = <0x01>;
				compatible = "fsl,imx6q-usbmisc";
				reg = <0x2184800 0x200>;
				clocks = <0x02 0xa2>;
				phandle = <0x2e>;
			};

			ethernet@2188000 {
				compatible = "fsl,imx6q-fec";
				reg = <0x2188000 0x4000>;
				interrupt-names = "int0", "pps";
				interrupts = <0x00 0x76 0x04 0x00 0x77 0x04>;
				clocks = <0x02 0x75 0x02 0x75 0x02 0xbe 0x02 0x10a>;
				clock-names = "ipg", "ahb", "ptp", "enet_clk_ref";
				fsl,stop-mode = <0x01 0x34 0x1b>;
				nvmem-cells = <0x35>;
				nvmem-cell-names = "mac-address";
				status = "okay";
				pinctrl-names = "default";
				pinctrl-0 = <0x36>;
				phy-mode = "rgmii";
				phy-handle = <0x37>;
				phy-reset-gpios = <0x16 0x17 0x01>;

				mdio {
					#address-cells = <0x01>;
					#size-cells = <0x00>;

					ethernet-phy {
						compatible = "ethernet-phy-ieee802.3-c22";
						txen-skew-ps = <0x00>;
						txc-skew-ps = <0xbb8>;
						rxdv-skew-ps = <0x00>;
						rxc-skew-ps = <0xbb8>;
						rxd0-skew-ps = <0x00>;
						rxd1-skew-ps = <0x00>;
						rxd2-skew-ps = <0x00>;
						rxd3-skew-ps = <0x00>;
						txd0-skew-ps = <0x00>;
						txd1-skew-ps = <0x00>;
						txd2-skew-ps = <0x00>;
						txd3-skew-ps = <0x00>;
						phandle = <0x37>;
					};
				};
			};

			mlb@218c000 {
				reg = <0x218c000 0x4000>;
				interrupts = <0x00 0x35 0x04 0x00 0x75 0x04 0x00 0x7e 0x04>;
			};

			mmc@2190000 {
				compatible = "fsl,imx6q-usdhc";
				reg = <0x2190000 0x4000>;
				interrupts = <0x00 0x16 0x04>;
				clocks = <0x02 0xa3 0x02 0xa3 0x02 0xa3>;
				clock-names = "ipg", "ahb", "per";
				bus-width = <0x04>;
				status = "disabled";
			};

			mmc@2194000 {
				compatible = "fsl,imx6q-usdhc";
				reg = <0x2194000 0x4000>;
				interrupts = <0x00 0x17 0x04>;
				clocks = <0x02 0xa4 0x02 0xa4 0x02 0xa4>;
				clock-names = "ipg", "ahb", "per";
				bus-width = <0x04>;
				status = "disabled";
			};

			mmc@2198000 {
				compatible = "fsl,imx6q-usdhc";
				reg = <0x2198000 0x4000>;
				interrupts = <0x00 0x18 0x04>;
				clocks = <0x02 0xa5 0x02 0xa5 0x02 0xa5>;
				clock-names = "ipg", "ahb", "per";
				bus-width = <0x04>;
				status = "okay";
				pinctrl-names = "default";
				pinctrl-0 = <0x38>;
				cd-gpios = <0x39 0x00 0x01>;
				wp-gpios = <0x39 0x01 0x00>;
				vmmc-supply = <0x3a>;
			};

			mmc@219c000 {
				compatible = "fsl,imx6q-usdhc";
				reg = <0x219c000 0x4000>;
				interrupts = <0x00 0x19 0x04>;
				clocks = <0x02 0xa6 0x02 0xa6 0x02 0xa6>;
				clock-names = "ipg", "ahb", "per";
				bus-width = <0x04>;
				status = "okay";
				pinctrl-names = "default";
				pinctrl-0 = <0x3b>;
				cd-gpios = <0x3c 0x06 0x01>;
				vmmc-supply = <0x3a>;
			};

			i2c@21a0000 {
				#address-cells = <0x01>;
				#size-cells = <0x00>;
				compatible = "fsl,imx6q-i2c", "fsl,imx21-i2c";
				reg = <0x21a0000 0x4000>;
				interrupts = <0x00 0x24 0x04>;
				clocks = <0x02 0x7d>;
				status = "okay";
				clock-frequency = <0x186a0>;
				pinctrl-names = "default";
				pinctrl-0 = <0x3d>;

				sgtl5000@a {
					compatible = "fsl,sgtl5000";
					reg = <0x0a>;
					#sound-dai-cells = <0x00>;
					clocks = <0x02 0xc9>;
					VDDA-supply = <0x3e>;
					VDDIO-supply = <0x3a>;
					phandle = <0x7e>;
				};
			};

			i2c@21a4000 {
				#address-cells = <0x01>;
				#size-cells = <0x00>;
				compatible = "fsl,imx6q-i2c", "fsl,imx21-i2c";
				reg = <0x21a4000 0x4000>;
				interrupts = <0x00 0x25 0x04>;
				clocks = <0x02 0x7e>;
				status = "okay";
				clock-frequency = <0x186a0>;
				pinctrl-names = "default";
				pinctrl-0 = <0x3f>;
				phandle = <0x0e>;

				camera@40 {
					compatible = "ovti,ov5640";
					pinctrl-names = "default";
					pinctrl-0 = <0x40>;
					reg = <0x40>;
					clocks = <0x41>;
					clock-names = "xclk";
					DOVDD-supply = <0x42>;
					AVDD-supply = <0x43>;
					DVDD-supply = <0x44>;
					reset-gpios = <0x3c 0x05 0x01>;
					powerdown-gpios = <0x45 0x09 0x00>;

					port {

						endpoint {
							remote-endpoint = <0x46>;
							clock-lanes = <0x00>;
							data-lanes = <0x01 0x02>;
							phandle = <0x50>;
						};
					};
				};

				camera@42 {
					compatible = "ovti,ov5642";
					pinctrl-names = "default";
					pinctrl-0 = <0x47>;
					clocks = <0x02 0xc8>;
					clock-names = "xclk";
					reg = <0x42>;
					reset-gpios = <0x48 0x08 0x01>;
					powerdown-gpios = <0x48 0x06 0x00>;
					gp-gpios = <0x48 0x10 0x00>;
					status = "disabled";

					port {

						endpoint {
							remote-endpoint = <0x49>;
							bus-width = <0x08>;
							hsync-active = <0x01>;
							vsync-active = <0x01>;
							phandle = <0x28>;
						};
					};
				};
			};

			i2c@21a8000 {
				#address-cells = <0x01>;
				#size-cells = <0x00>;
				compatible = "fsl,imx6q-i2c", "fsl,imx21-i2c";
				reg = <0x21a8000 0x4000>;
				interrupts = <0x00 0x26 0x04>;
				clocks = <0x02 0x7f>;
				status = "okay";
				clock-frequency = <0x186a0>;
				pinctrl-names = "default";
				pinctrl-0 = <0x4a>;
			};

			romcp@21ac000 {
				reg = <0x21ac000 0x4000>;
			};

			memory-controller@21b0000 {
				compatible = "fsl,imx6q-mmdc";
				reg = <0x21b0000 0x4000>;
				clocks = <0x02 0x107>;
			};

			memory-controller@21b4000 {
				compatible = "fsl,imx6q-mmdc";
				reg = <0x21b4000 0x4000>;
				status = "disabled";
			};

			memory-controller@21b8000 {
				#address-cells = <0x02>;
				#size-cells = <0x01>;
				compatible = "fsl,imx6q-weim";
				reg = <0x21b8000 0x4000>;
				interrupts = <0x00 0x0e 0x04>;
				clocks = <0x02 0xc4>;
				fsl,weim-cs-gpr = <0x01>;
				status = "disabled";
			};

			efuse@21bc000 {
				compatible = "fsl,imx6q-ocotp", "syscon";
				reg = <0x21bc000 0x4000>;
				clocks = <0x02 0x80>;
				#address-cells = <0x01>;
				#size-cells = <0x01>;

				speed-grade@10 {
					reg = <0x10 0x04>;
					phandle = <0x6f>;
				};

				calib@38 {
					reg = <0x38 0x04>;
					phandle = <0x22>;
				};

				temp-grade@20 {
					reg = <0x20 0x04>;
					phandle = <0x23>;
				};

				mac-addr@88 {
					reg = <0x88 0x06>;
					phandle = <0x35>;
				};
			};

			tzasc@21d0000 {
				reg = <0x21d0000 0x4000>;
				interrupts = <0x00 0x6c 0x04>;
			};

			tzasc@21d4000 {
				reg = <0x21d4000 0x4000>;
				interrupts = <0x00 0x6d 0x04>;
			};

			audmux@21d8000 {
				compatible = "fsl,imx6q-audmux", "fsl,imx31-audmux";
				reg = <0x21d8000 0x4000>;
				status = "okay";
				pinctrl-names = "default";
				pinctrl-0 = <0x4b>;
			};

			mipi@21dc000 {
				compatible = "fsl,imx6-mipi-csi2";
				reg = <0x21dc000 0x4000>;
				#address-cells = <0x01>;
				#size-cells = <0x00>;
				interrupts = <0x00 0x64 0x04 0x00 0x65 0x04>;
				clocks = <0x02 0x8a 0x02 0xee 0x02 0x61>;
				clock-names = "dphy", "ref", "pix";
				status = "okay";

				port@1 {
					reg = <0x01>;

					endpoint {
						remote-endpoint = <0x4c>;
						phandle = <0x27>;
					};
				};

				port@2 {
					reg = <0x02>;

					endpoint {
						remote-endpoint = <0x4d>;
						phandle = <0x58>;
					};
				};

				port@3 {
					reg = <0x03>;

					endpoint {
						remote-endpoint = <0x4e>;
						phandle = <0x62>;
					};
				};

				port@4 {
					reg = <0x04>;

					endpoint {
						remote-endpoint = <0x4f>;
						phandle = <0x2a>;
					};
				};

				port@0 {
					reg = <0x00>;

					endpoint {
						remote-endpoint = <0x50>;
						clock-lanes = <0x00>;
						data-lanes = <0x01 0x02>;
						phandle = <0x46>;
					};
				};
			};

			mipi@21e0000 {
				reg = <0x21e0000 0x4000>;
				status = "disabled";

				ports {
					#address-cells = <0x01>;
					#size-cells = <0x00>;

					port@0 {
						reg = <0x00>;

						endpoint {
							remote-endpoint = <0x51>;
							phandle = <0x5b>;
						};
					};

					port@1 {
						reg = <0x01>;

						endpoint {
							remote-endpoint = <0x52>;
							phandle = <0x5f>;
						};
					};

					port@2 {
						reg = <0x02>;

						endpoint {
							remote-endpoint = <0x53>;
							phandle = <0x65>;
						};
					};

					port@3 {
						reg = <0x03>;

						endpoint {
							remote-endpoint = <0x54>;
							phandle = <0x69>;
						};
					};
				};
			};

			vdoa@21e4000 {
				compatible = "fsl,imx6q-vdoa";
				reg = <0x21e4000 0x4000>;
				interrupts = <0x00 0x12 0x04>;
				clocks = <0x02 0xca>;
			};

			serial@21e8000 {
				compatible = "fsl,imx6q-uart", "fsl,imx21-uart";
				reg = <0x21e8000 0x4000>;
				interrupts = <0x00 0x1b 0x04>;
				clocks = <0x02 0xa0 0x02 0xa1>;
				clock-names = "ipg", "per";
				dmas = <0x15 0x1b 0x04 0x00 0x15 0x1c 0x04 0x00>;
				dma-names = "rx", "tx";
				status = "okay";
				pinctrl-names = "default";
				pinctrl-0 = <0x55>;
			};

			serial@21ec000 {
				compatible = "fsl,imx6q-uart", "fsl,imx21-uart";
				reg = <0x21ec000 0x4000>;
				interrupts = <0x00 0x1c 0x04>;
				clocks = <0x02 0xa0 0x02 0xa1>;
				clock-names = "ipg", "per";
				dmas = <0x15 0x1d 0x04 0x00 0x15 0x1e 0x04 0x00>;
				dma-names = "rx", "tx";
				status = "disabled";
			};

			serial@21f0000 {
				compatible = "fsl,imx6q-uart", "fsl,imx21-uart";
				reg = <0x21f0000 0x4000>;
				interrupts = <0x00 0x1d 0x04>;
				clocks = <0x02 0xa0 0x02 0xa1>;
				clock-names = "ipg", "per";
				dmas = <0x15 0x1f 0x04 0x00 0x15 0x20 0x04 0x00>;
				dma-names = "rx", "tx";
				status = "disabled";
			};

			serial@21f4000 {
				compatible = "fsl,imx6q-uart", "fsl,imx21-uart";
				reg = <0x21f4000 0x4000>;
				interrupts = <0x00 0x1e 0x04>;
				clocks = <0x02 0xa0 0x02 0xa1>;
				clock-names = "ipg", "per";
				dmas = <0x15 0x21 0x04 0x00 0x15 0x22 0x04 0x00>;
				dma-names = "rx", "tx";
				status = "disabled";
			};
		};

		ipu@2400000 {
			#address-cells = <0x01>;
			#size-cells = <0x00>;
			compatible = "fsl,imx6q-ipu";
			reg = <0x2400000 0x400000>;
			interrupts = <0x00 0x06 0x04 0x00 0x05 0x04>;
			clocks = <0x02 0x82 0x02 0x83 0x02 0x84>;
			clock-names = "bus", "di0", "di1";
			resets = <0x19 0x02>;

			port@0 {
				reg = <0x00>;
				pinctrl-names = "default";
				pinctrl-0 = <0x56>;
				phandle = <0x70>;

				endpoint {
					remote-endpoint = <0x57>;
					bus-width = <0x08>;
					data-shift = <0x0c>;
					hsync-active = <0x01>;
					vync-active = <0x01>;
					phandle = <0x29>;
				};
			};

			port@1 {
				reg = <0x01>;
				phandle = <0x71>;

				endpoint {
					remote-endpoint = <0x58>;
					clock-lanes = <0x00>;
					data-lanes = <0x01 0x02>;
					phandle = <0x4d>;
				};
			};

			port@2 {
				#address-cells = <0x01>;
				#size-cells = <0x00>;
				reg = <0x02>;
				phandle = <0x74>;

				endpoint@0 {
					reg = <0x00>;
					remote-endpoint = <0x59>;
					phandle = <0x82>;
				};

				endpoint@1 {
					reg = <0x01>;
					remote-endpoint = <0x5a>;
					phandle = <0x0f>;
				};

				endpoint@2 {
					reg = <0x02>;
					remote-endpoint = <0x5b>;
					phandle = <0x51>;
				};

				endpoint@3 {
					reg = <0x03>;
					remote-endpoint = <0x5c>;
					phandle = <0x03>;
				};

				endpoint@4 {
					reg = <0x04>;
					remote-endpoint = <0x5d>;
					phandle = <0x08>;
				};
			};

			port@3 {
				#address-cells = <0x01>;
				#size-cells = <0x00>;
				reg = <0x03>;
				phandle = <0x75>;

				endpoint@0 {
					reg = <0x00>;
				};

				endpoint@1 {
					reg = <0x01>;
					remote-endpoint = <0x5e>;
					phandle = <0x10>;
				};

				endpoint@2 {
					reg = <0x02>;
					remote-endpoint = <0x5f>;
					phandle = <0x52>;
				};

				endpoint@3 {
					reg = <0x03>;
					remote-endpoint = <0x60>;
					phandle = <0x04>;
				};

				endpoint@4 {
					reg = <0x04>;
					remote-endpoint = <0x61>;
					phandle = <0x09>;
				};
			};
		};

		sram@900000 {
			compatible = "mmio-sram";
			reg = <0x900000 0x40000>;
			ranges = <0x00 0x900000 0x40000>;
			#address-cells = <0x01>;
			#size-cells = <0x01>;
			clocks = <0x02 0x8e>;
			phandle = <0x1a>;
		};

		sata@2200000 {
			compatible = "fsl,imx6q-ahci";
			reg = <0x2200000 0x4000>;
			interrupts = <0x00 0x27 0x04>;
			clocks = <0x02 0x9a 0x02 0xbb 0x02 0x69>;
			clock-names = "sata", "sata_ref", "ahb";
			status = "okay";
		};

		gpu@2204000 {
			compatible = "vivante,gc";
			reg = <0x2204000 0x4000>;
			interrupts = <0x00 0x0b 0x04>;
			clocks = <0x02 0x8f 0x02 0x79>;
			clock-names = "bus", "core";
			power-domains = <0x13>;
			#cooling-cells = <0x02>;
		};

		ipu@2800000 {
			#address-cells = <0x01>;
			#size-cells = <0x00>;
			compatible = "fsl,imx6q-ipu";
			reg = <0x2800000 0x400000>;
			interrupts = <0x00 0x08 0x04 0x00 0x07 0x04>;
			clocks = <0x02 0x85 0x02 0x86 0x02 0x89>;
			clock-names = "bus", "di0", "di1";
			resets = <0x19 0x04>;

			port@0 {
				reg = <0x00>;
				phandle = <0x72>;

				endpoint {
					remote-endpoint = <0x62>;
					phandle = <0x4e>;
				};
			};

			port@1 {
				reg = <0x01>;
				phandle = <0x73>;

				endpoint {
					remote-endpoint = <0x63>;
					phandle = <0x2b>;
				};
			};

			port@2 {
				#address-cells = <0x01>;
				#size-cells = <0x00>;
				reg = <0x02>;
				phandle = <0x76>;

				endpoint@0 {
					reg = <0x00>;
				};

				endpoint@1 {
					reg = <0x01>;
					remote-endpoint = <0x64>;
					phandle = <0x11>;
				};

				endpoint@2 {
					reg = <0x02>;
					remote-endpoint = <0x65>;
					phandle = <0x53>;
				};

				endpoint@3 {
					reg = <0x03>;
					remote-endpoint = <0x66>;
					phandle = <0x05>;
				};

				endpoint@4 {
					reg = <0x04>;
					remote-endpoint = <0x67>;
					phandle = <0x0a>;
				};
			};

			port@3 {
				#address-cells = <0x01>;
				#size-cells = <0x00>;
				reg = <0x03>;
				phandle = <0x77>;

				endpoint@1 {
					reg = <0x01>;
					remote-endpoint = <0x68>;
					phandle = <0x12>;
				};

				endpoint@2 {
					reg = <0x02>;
					remote-endpoint = <0x69>;
					phandle = <0x54>;
				};

				endpoint@3 {
					reg = <0x03>;
					remote-endpoint = <0x6a>;
					phandle = <0x06>;
				};

				endpoint@4 {
					reg = <0x04>;
					remote-endpoint = <0x6b>;
					phandle = <0x0b>;
				};
			};
		};
	};

	cpus {
		#address-cells = <0x01>;
		#size-cells = <0x00>;

		cpu@0 {
			compatible = "arm,cortex-a9";
			device_type = "cpu";
			reg = <0x00>;
			next-level-cache = <0x6c>;
			operating-points = <0x124f80 0x137478 0xf32a0 0x1312d0 0xd0020 0x1312d0 0xc15c0 0x11edd8 0x60ae0 0xee098>;
			fsl,soc-operating-points = <0x124f80 0x137478 0xf32a0 0x1312d0 0xd0020 0x1312d0 0xc15c0 0x11edd8 0x60ae0 0x11edd8>;
			clock-latency = <0xee6c>;
			#cooling-cells = <0x02>;
			clocks = <0x02 0x68 0x02 0x06 0x02 0x10 0x02 0x11 0x02 0xaa>;
			clock-names = "arm", "pll2_pfd2_396m", "step", "pll1_sw", "pll1_sys";
			arm-supply = <0x6d>;
			pu-supply = <0x25>;
			soc-supply = <0x6e>;
			nvmem-cells = <0x6f>;
			nvmem-cell-names = "speed_grade";
		};

		cpu@1 {
			compatible = "arm,cortex-a9";
			device_type = "cpu";
			reg = <0x01>;
			next-level-cache = <0x6c>;
			operating-points = <0x124f80 0x137478 0xf32a0 0x1312d0 0xd0020 0x1312d0 0xc15c0 0x11edd8 0x60ae0 0xee098>;
			fsl,soc-operating-points = <0x124f80 0x137478 0xf32a0 0x1312d0 0xd0020 0x1312d0 0xc15c0 0x11edd8 0x60ae0 0x11edd8>;
			clock-latency = <0xee6c>;
			#cooling-cells = <0x02>;
			clocks = <0x02 0x68 0x02 0x06 0x02 0x10 0x02 0x11 0x02 0xaa>;
			clock-names = "arm", "pll2_pfd2_396m", "step", "pll1_sw", "pll1_sys";
			arm-supply = <0x6d>;
			pu-supply = <0x25>;
			soc-supply = <0x6e>;
		};

		cpu@2 {
			compatible = "arm,cortex-a9";
			device_type = "cpu";
			reg = <0x02>;
			next-level-cache = <0x6c>;
			operating-points = <0x124f80 0x137478 0xf32a0 0x1312d0 0xd0020 0x1312d0 0xc15c0 0x11edd8 0x60ae0 0xee098>;
			fsl,soc-operating-points = <0x124f80 0x137478 0xf32a0 0x1312d0 0xd0020 0x1312d0 0xc15c0 0x11edd8 0x60ae0 0x11edd8>;
			clock-latency = <0xee6c>;
			#cooling-cells = <0x02>;
			clocks = <0x02 0x68 0x02 0x06 0x02 0x10 0x02 0x11 0x02 0xaa>;
			clock-names = "arm", "pll2_pfd2_396m", "step", "pll1_sw", "pll1_sys";
			arm-supply = <0x6d>;
			pu-supply = <0x25>;
			soc-supply = <0x6e>;
		};

		cpu@3 {
			compatible = "arm,cortex-a9";
			device_type = "cpu";
			reg = <0x03>;
			next-level-cache = <0x6c>;
			operating-points = <0x124f80 0x137478 0xf32a0 0x1312d0 0xd0020 0x1312d0 0xc15c0 0x11edd8 0x60ae0 0xee098>;
			fsl,soc-operating-points = <0x124f80 0x137478 0xf32a0 0x1312d0 0xd0020 0x1312d0 0xc15c0 0x11edd8 0x60ae0 0x11edd8>;
			clock-latency = <0xee6c>;
			#cooling-cells = <0x02>;
			clocks = <0x02 0x68 0x02 0x06 0x02 0x10 0x02 0x11 0x02 0xaa>;
			clock-names = "arm", "pll2_pfd2_396m", "step", "pll1_sw", "pll1_sys";
			arm-supply = <0x6d>;
			pu-supply = <0x25>;
			soc-supply = <0x6e>;
		};
	};

	capture-subsystem {
		compatible = "fsl,imx-capture-subsystem";
		ports = <0x70 0x71 0x72 0x73>;
	};

	display-subsystem {
		compatible = "fsl,imx-display-subsystem";
		ports = <0x74 0x75 0x76 0x77>;
	};

	memory@10000000 {
		device_type = "memory";
		reg = <0x10000000 0x40000000>;
	};

	regulator-2p5v {
		compatible = "regulator-fixed";
		regulator-name = "2P5V";
		regulator-min-microvolt = <0x2625a0>;
		regulator-max-microvolt = <0x2625a0>;
		regulator-always-on;
		phandle = <0x3e>;
	};

	regulator-3p3v {
		compatible = "regulator-fixed";
		regulator-name = "3P3V";
		regulator-min-microvolt = <0x325aa0>;
		regulator-max-microvolt = <0x325aa0>;
		regulator-always-on;
		phandle = <0x3a>;
	};

	regulator-usb-otg-vbus {
		compatible = "regulator-fixed";
		regulator-name = "usb_otg_vbus";
		regulator-min-microvolt = <0x4c4b40>;
		regulator-max-microvolt = <0x4c4b40>;
		gpio = <0x16 0x16 0x00>;
		enable-active-high;
		phandle = <0x2f>;
	};

	regulator-can-xcvr {
		compatible = "regulator-fixed";
		regulator-name = "CAN XCVR";
		regulator-min-microvolt = <0x325aa0>;
		regulator-max-microvolt = <0x325aa0>;
		pinctrl-names = "default";
		pinctrl-0 = <0x78>;
		gpio = <0x48 0x02 0x01>;
		phandle = <0x1f>;
	};

	regulator-1p5v {
		compatible = "regulator-fixed";
		regulator-name = "1P5V";
		regulator-min-microvolt = <0x16e360>;
		regulator-max-microvolt = <0x16e360>;
		regulator-always-on;
		phandle = <0x44>;
	};

	regulator-1p8v {
		compatible = "regulator-fixed";
		regulator-name = "1P8V";
		regulator-min-microvolt = <0x1b7740>;
		regulator-max-microvolt = <0x1b7740>;
		regulator-always-on;
		phandle = <0x42>;
	};

	regulator-2p8v {
		compatible = "regulator-fixed";
		regulator-name = "2P8V";
		regulator-min-microvolt = <0x2ab980>;
		regulator-max-microvolt = <0x2ab980>;
		regulator-always-on;
		phandle = <0x43>;
	};

	regulator-usb-h1-vbus {
		compatible = "regulator-fixed";
		pinctrl-names = "default";
		pinctrl-0 = <0x79>;
		regulator-name = "usb_h1_vbus";
		regulator-min-microvolt = <0x325aa0>;
		regulator-max-microvolt = <0x325aa0>;
		gpio = <0x39 0x0c 0x00>;
		enable-active-high;
		phandle = <0x32>;
	};

	mipi_xclk {
		compatible = "pwm-clock";
		#clock-cells = <0x00>;
		clock-frequency = <0x14fb180>;
		clock-output-names = "mipi_pwm3";
		pwms = <0x7a 0x00 0x2d 0x00>;
		status = "okay";
		phandle = <0x41>;
	};

	gpio-keys {
		compatible = "gpio-keys";
		pinctrl-names = "default";
		pinctrl-0 = <0x7b>;

		power {
			label = "Power Button";
			gpios = <0x3c 0x03 0x01>;
			linux,code = <0x74>;
			wakeup-source;
		};

		menu {
			label = "Menu";
			gpios = <0x3c 0x01 0x01>;
			linux,code = <0x8b>;
		};

		home {
			label = "Home";
			gpios = <0x3c 0x04 0x01>;
			linux,code = <0x66>;
		};

		back {
			label = "Back";
			gpios = <0x3c 0x02 0x01>;
			linux,code = <0x9e>;
		};

		volume-up {
			label = "Volume Up";
			gpios = <0x39 0x0d 0x01>;
			linux,code = <0x73>;
		};

		volume-down {
			label = "Volume Down";
			gpios = <0x7c 0x05 0x01>;
			linux,code = <0x72>;
		};
	};

	sound {
		compatible = "fsl,imx6q-sabrelite-sgtl5000", "fsl,imx-audio-sgtl5000";
		model = "imx6q-sabrelite-sgtl5000";
		ssi-controller = <0x7d>;
		audio-codec = <0x7e>;
		audio-routing = "MIC_IN", "Mic Jack", "Mic Jack", "Mic Bias", "Headphone Jack", "HP_OUT";
		mux-int-port = <0x01>;
		mux-ext-port = <0x04>;
	};

	backlight-lcd {
		compatible = "pwm-backlight";
		pwms = <0x7f 0x00 0x4c4b40 0x00>;
		brightness-levels = <0x00 0x04 0x08 0x10 0x20 0x40 0x80 0xff>;
		default-brightness-level = <0x07>;
		power-supply = <0x3a>;
		status = "okay";
		phandle = <0x84>;
	};

	backlight-lvds {
		compatible = "pwm-backlight";
		pwms = <0x80 0x00 0x4c4b40 0x00>;
		brightness-levels = <0x00 0x04 0x08 0x10 0x20 0x40 0x80 0xff>;
		default-brightness-level = <0x07>;
		power-supply = <0x3a>;
		status = "okay";
		phandle = <0x86>;
	};

	disp0 {
		compatible = "fsl,imx-parallel-display";
		#address-cells = <0x01>;
		#size-cells = <0x00>;
		interface-pix-fmt = "bgr666";
		pinctrl-names = "default";
		pinctrl-0 = <0x81>;
		status = "okay";

		port@0 {
			reg = <0x00>;

			endpoint {
				remote-endpoint = <0x82>;
				phandle = <0x59>;
			};
		};

		port@1 {
			reg = <0x01>;

			endpoint {
				remote-endpoint = <0x83>;
				phandle = <0x85>;
			};
		};
	};

	panel-lcd {
		compatible = "okaya,rs800480t-7x0gp";
		backlight = <0x84>;

		port {

			endpoint {
				remote-endpoint = <0x85>;
				phandle = <0x83>;
			};
		};
	};

	panel-lvds0 {
		compatible = "hannstar,hsd100pxn1";
		backlight = <0x86>;

		port {

			endpoint {
				remote-endpoint = <0x87>;
				phandle = <0x07>;
			};
		};
	};
};
